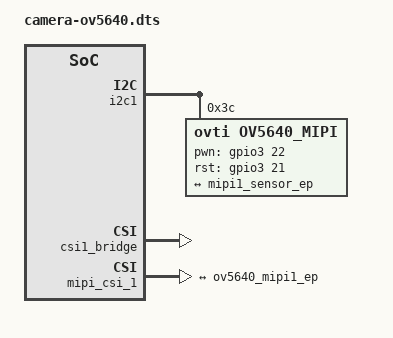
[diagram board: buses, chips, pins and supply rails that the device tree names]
/*
 * Copyright 2023 AVNET
 *
 * This program is free software; you can redistribute it and/or
 * modify it under the terms of the GNU General Public License
 * as published by the Free Software Foundation; either version 2
 * of the License, or (at your option) any later version.
 *
 * This program is distributed in the hope that it will be useful,
 * but WITHOUT ANY WARRANTY; without even the implied warranty of
 * MERCHANTABILITY or FITNESS FOR A PARTICULAR PURPOSE.  See the
 * GNU General Public License for more details.
 */

/dts-v1/;
/plugin/;

#include <dt-bindings/clock/imx8mm-clock.h>
#include <dt-bindings/gpio/gpio.h>

/* Device tree overlay for MIPI-CSI2 OV5640 camera */

&i2c1{
	status = "okay";

	#address-cells = <1>;
	#size-cells = <0>;

	ov5640_mipi@3c {
		compatible = "ovti,ov5640_mipi";
		reg = <0x3c>;
		pinctrl-names = "default";
		pinctrl-0 = <&pinctrl_csi1>;
		clocks = <&clk IMX8MM_CLK_CLKO1>;
		clock-names = "csi_mclk";
		csi_id = <0>;
		pwn-gpios = <&gpio3 22 GPIO_ACTIVE_HIGH>;
		rst-gpios = <&gpio3 21 GPIO_ACTIVE_HIGH>;
		status = "okay";

		mclk = <24000000>;
		mclk_source = <0>;
		port {
			ov5640_mipi1_ep: endpoint {
				remote-endpoint = <&mipi1_sensor_ep>;
			};
		};
	};
};


&csi1_bridge{
	status = "okay";
};

&mipi_csi_1{
	status = "okay";

	port {
		mipi1_sensor_ep: endpoint@1 {
			remote-endpoint = <&ov5640_mipi1_ep>;
			data-lanes = <2>;
			csis-hs-settle = <13>;
			csis-clk-settle = <2>;
			csis-wclk;
		};
	};
};

